AUTOSAR XML (schema 00050)
package /SwComponentTypes
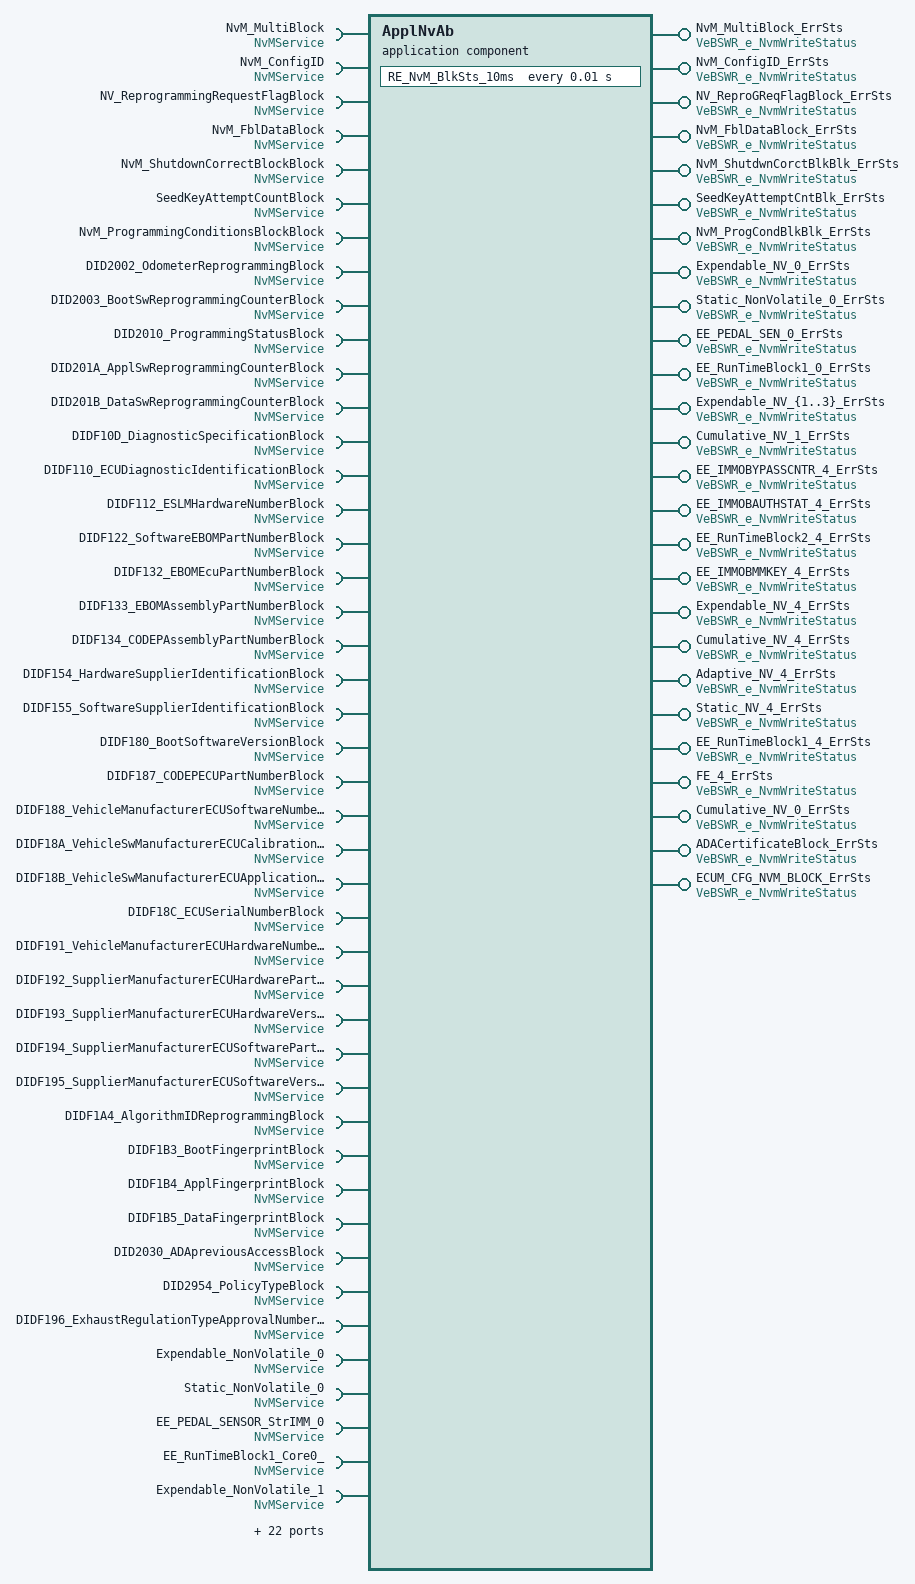
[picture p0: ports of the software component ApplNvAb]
  application sw component type ApplNvAb
    75 x require port, all with required-interface=NvMService:
      NvM_MultiBlock
      NvM_ConfigID
      NV_ReprogrammingRequestFlagBlock
      NvM_FblDataBlock
      NvM_ShutdownCorrectBlockBlock
      SeedKeyAttemptCountBlock
      NvM_ProgrammingConditionsBlockBlock
      DID2002_OdometerReprogrammingBlock
      DID2003_BootSwReprogrammingCounterBlock
      DID2010_ProgrammingStatusBlock
      DID201A_ApplSwReprogrammingCounterBlock
      DID201B_DataSwReprogrammingCounterBlock
      DIDF10D_DiagnosticSpecificationBlock
      DIDF110_ECUDiagnosticIdentificationBlock
      DIDF112_ESLMHardwareNumberBlock
      DIDF122_SoftwareEBOMPartNumberBlock
      DIDF132_EBOMEcuPartNumberBlock
      DIDF133_EBOMAssemblyPartNumberBlock
      DIDF134_CODEPAssemblyPartNumberBlock
      DIDF154_HardwareSupplierIdentificationBlock
      DIDF155_SoftwareSupplierIdentificationBlock
      DIDF180_BootSoftwareVersionBlock
      DIDF187_CODEPECUPartNumberBlock
      DIDF188_VehicleManufacturerECUSoftwareNumberBlock
      DIDF18A_VehicleSwManufacturerECUCalibrationNumberBlock
      DIDF18B_VehicleSwManufacturerECUApplicationNumberBlock
      DIDF18C_ECUSerialNumberBlock
      DIDF191_VehicleManufacturerECUHardwareNumberBlock
      DIDF192_SupplierManufacturerECUHardwarePartNumberBlock
      DIDF193_SupplierManufacturerECUHardwareVersionNumberBlock
      DIDF194_SupplierManufacturerECUSoftwarePartNumberBlock
      DIDF195_SupplierManufacturerECUSoftwareVersionNumberBlock
      DIDF1A4_AlgorithmIDReprogrammingBlock
      DIDF1B3_BootFingerprintBlock
      DIDF1B4_ApplFingerprintBlock
      DIDF1B5_DataFingerprintBlock
      DID2030_ADApreviousAccessBlock
      DID2954_PolicyTypeBlock
      DIDF196_ExhaustRegulationTypeApprovalNumberBlock
      Expendable_NonVolatile_0
      Static_NonVolatile_0
      EE_PEDAL_SENSOR_StrIMM_0
      EE_RunTimeBlock1_Core0_
      Expendable_NonVolatile_1
      Expendable_NonVolatile_Core2
      Expendable_NonVolatile_3
      Cumulative_NonVolatile_1
      EE_IMMOBYPASSCNTR_StrIMM_4
      EE_IMMOBILIZERAUTHSTAT_StrIMM_4
      EE_RunTimeBlock2_Core4
      EE_IMMOBILIZERMMKEY_StrIMM_4
      Expendable_NonVolatile_4
      Cumulative_NonVolatile_4
      Adaptive_NonVolatile_4
      Static_NonVolatile_4
      EE_RunTimeBlock1_Core4
      FE_4
      Cumulative_NonVolatile_0
      DID2023_PROXIWriteData
      BSWDiag_Data_blk_Desc_Core0
      NvM_Dem_IdIndicatorAttributes
      NvMBlockDescriptor_Dem_GenericNvData
      NvMBlockDescriptor_Dem_AllEventsStatusByte
      NvMBlockDescriptor_Dem_EvMemEventMemory{0..9}
      ADACertificateBlock
      ECUM_CFG_NVM_BLOCK
    28 x provide port, all with provided-interface=VeBSWR_e_NvmWriteStatus:
      NvM_MultiBlock_ErrSts
      NvM_ConfigID_ErrSts
      NV_ReproGReqFlagBlock_ErrSts
      NvM_FblDataBlock_ErrSts
      NvM_ShutdwnCorctBlkBlk_ErrSts
      SeedKeyAttemptCntBlk_ErrSts
      NvM_ProgCondBlkBlk_ErrSts
      Expendable_NV_0_ErrSts
      Static_NonVolatile_0_ErrSts
      EE_PEDAL_SEN_0_ErrSts
      EE_RunTimeBlock1_0_ErrSts
      Expendable_NV_{1..3}_ErrSts
      Cumulative_NV_1_ErrSts
      EE_IMMOBYPASSCNTR_4_ErrSts
      EE_IMMOBAUTHSTAT_4_ErrSts
      EE_RunTimeBlock2_4_ErrSts
      EE_IMMOBMMKEY_4_ErrSts
      Expendable_NV_4_ErrSts
      Cumulative_NV_4_ErrSts
      Adaptive_NV_4_ErrSts
      Static_NV_4_ErrSts
      EE_RunTimeBlock1_4_ErrSts
      FE_4_ErrSts
      Cumulative_NV_0_ErrSts
      ADACertificateBlock_ErrSts
      ECUM_CFG_NVM_BLOCK_ErrSts
    behavior IBApplNvAb
      timing event RE_NvM_BlkErrSts_10ms: start-on-event=RE_NvM_BlkSts_10ms, period=0.01
      runnable RE_NvM_BlkSts_10ms
        data-send-points:
          28 x access:
            DSP_VeBSWR_e_NvmWriteStatus_0: accessed-variable=ADACertificateBlock_ErrSts.VeBSWR_e_NvmWriteStatus
            DSP_VeBSWR_e_NvmWriteStatus_1: accessed-variable=Cumulative_NV_4_ErrSts.VeBSWR_e_NvmWriteStatus
            DSP_VeBSWR_e_NvmWriteStatus_2: accessed-variable=SeedKeyAttemptCntBlk_ErrSts.VeBSWR_e_NvmWriteStatus
            DSP_VeBSWR_e_NvmWriteStatus_3: accessed-variable=Expendable_NV_3_ErrSts.VeBSWR_e_NvmWriteStatus
            DSP_VeBSWR_e_NvmWriteStatus_4: accessed-variable=Cumulative_NV_1_ErrSts.VeBSWR_e_NvmWriteStatus
            DSP_VeBSWR_e_NvmWriteStatus_5: accessed-variable=NvM_ShutdwnCorctBlkBlk_ErrSts.VeBSWR_e_NvmWriteStatus
            DSP_VeBSWR_e_NvmWriteStatus_6: accessed-variable=Expendable_NV_1_ErrSts.VeBSWR_e_NvmWriteStatus
            DSP_VeBSWR_e_NvmWriteStatus_7: accessed-variable=NvM_MultiBlock_ErrSts.VeBSWR_e_NvmWriteStatus
            DSP_VeBSWR_e_NvmWriteStatus_8: accessed-variable=EE_IMMOBYPASSCNTR_4_ErrSts.VeBSWR_e_NvmWriteStatus
            DSP_VeBSWR_e_NvmWriteStatus_9: accessed-variable=Expendable_NV_0_ErrSts.VeBSWR_e_NvmWriteStatus
            DSP_VeBSWR_e_NvmWriteStatus_10: accessed-variable=Expendable_NV_4_ErrSts.VeBSWR_e_NvmWriteStatus
            DSP_VeBSWR_e_NvmWriteStatus_11: accessed-variable=NV_ReproGReqFlagBlock_ErrSts.VeBSWR_e_NvmWriteStatus
            DSP_VeBSWR_e_NvmWriteStatus_12: accessed-variable=FE_4_ErrSts.VeBSWR_e_NvmWriteStatus
            DSP_VeBSWR_e_NvmWriteStatus_13: accessed-variable=EE_RunTimeBlock2_4_ErrSts.VeBSWR_e_NvmWriteStatus
            DSP_VeBSWR_e_NvmWriteStatus_14: accessed-variable=Static_NonVolatile_0_ErrSts.VeBSWR_e_NvmWriteStatus
            DSP_VeBSWR_e_NvmWriteStatus_15: accessed-variable=EE_RunTimeBlock1_0_ErrSts.VeBSWR_e_NvmWriteStatus
            DSP_VeBSWR_e_NvmWriteStatus_16: accessed-variable=NvM_ConfigID_ErrSts.VeBSWR_e_NvmWriteStatus
            DSP_VeBSWR_e_NvmWriteStatus_17: accessed-variable=Expendable_NV_2_ErrSts.VeBSWR_e_NvmWriteStatus
            DSP_VeBSWR_e_NvmWriteStatus_18: accessed-variable=EE_IMMOBAUTHSTAT_4_ErrSts.VeBSWR_e_NvmWriteStatus
            DSP_VeBSWR_e_NvmWriteStatus_19: accessed-variable=Static_NV_4_ErrSts.VeBSWR_e_NvmWriteStatus
            DSP_VeBSWR_e_NvmWriteStatus_20: accessed-variable=EE_IMMOBMMKEY_4_ErrSts.VeBSWR_e_NvmWriteStatus
            DSP_VeBSWR_e_NvmWriteStatus_21: accessed-variable=ECUM_CFG_NVM_BLOCK_ErrSts.VeBSWR_e_NvmWriteStatus
            DSP_VeBSWR_e_NvmWriteStatus_22: accessed-variable=Adaptive_NV_4_ErrSts.VeBSWR_e_NvmWriteStatus
            DSP_VeBSWR_e_NvmWriteStatus_23: accessed-variable=EE_RunTimeBlock1_4_ErrSts.VeBSWR_e_NvmWriteStatus
            DSP_VeBSWR_e_NvmWriteStatus_24: accessed-variable=NvM_FblDataBlock_ErrSts.VeBSWR_e_NvmWriteStatus
            DSP_VeBSWR_e_NvmWriteStatus_25: accessed-variable=EE_PEDAL_SEN_0_ErrSts.VeBSWR_e_NvmWriteStatus
            DSP_VeBSWR_e_NvmWriteStatus_26: accessed-variable=Cumulative_NV_0_ErrSts.VeBSWR_e_NvmWriteStatus
            DSP_VeBSWR_e_NvmWriteStatus_27: accessed-variable=NvM_ProgCondBlkBlk_ErrSts.VeBSWR_e_NvmWriteStatus
        75 x sync call:
          SynchronousServerCallPoint_0: operation=NvM_MultiBlock.GetErrorStatus
          SynchronousServerCallPoint_1: operation=NvM_ConfigID.GetErrorStatus
          SynchronousServerCallPoint_2: operation=NV_ReprogrammingRequestFlagBlock.GetErrorStatus
          SynchronousServerCallPoint_3: operation=NvM_FblDataBlock.GetErrorStatus
          SynchronousServerCallPoint_4: operation=NvM_ShutdownCorrectBlockBlock.GetErrorStatus
          SynchronousServerCallPoint_5: operation=SeedKeyAttemptCountBlock.GetErrorStatus
          SynchronousServerCallPoint_6: operation=NvM_ProgrammingConditionsBlockBlock.GetErrorStatus
          SynchronousServerCallPoint_7: operation=DID2002_OdometerReprogrammingBlock.GetErrorStatus
          SynchronousServerCallPoint_8: operation=DID2003_BootSwReprogrammingCounterBlock.GetErrorStatus
          SynchronousServerCallPoint_9: operation=DID2010_ProgrammingStatusBlock.GetErrorStatus
          SynchronousServerCallPoint_10: operation=DID201A_ApplSwReprogrammingCounterBlock.GetErrorStatus
          SynchronousServerCallPoint_11: operation=DID201B_DataSwReprogrammingCounterBlock.GetErrorStatus
          SynchronousServerCallPoint_12: operation=DIDF10D_DiagnosticSpecificationBlock.GetErrorStatus
          SynchronousServerCallPoint_13: operation=DIDF110_ECUDiagnosticIdentificationBlock.GetErrorStatus
          SynchronousServerCallPoint_14: operation=DIDF112_ESLMHardwareNumberBlock.GetErrorStatus
          SynchronousServerCallPoint_15: operation=DIDF122_SoftwareEBOMPartNumberBlock.GetErrorStatus
          SynchronousServerCallPoint_16: operation=DIDF132_EBOMEcuPartNumberBlock.GetErrorStatus
          SynchronousServerCallPoint_17: operation=DIDF133_EBOMAssemblyPartNumberBlock.GetErrorStatus
          SynchronousServerCallPoint_18: operation=DIDF134_CODEPAssemblyPartNumberBlock.GetErrorStatus
          SynchronousServerCallPoint_19: operation=DIDF154_HardwareSupplierIdentificationBlock.GetErrorStatus
          SynchronousServerCallPoint_20: operation=DIDF155_SoftwareSupplierIdentificationBlock.GetErrorStatus
          SynchronousServerCallPoint_21: operation=DIDF180_BootSoftwareVersionBlock.GetErrorStatus
          SynchronousServerCallPoint_22: operation=DIDF187_CODEPECUPartNumberBlock.GetErrorStatus
          SynchronousServerCallPoint_23: operation=DIDF188_VehicleManufacturerECUSoftwareNumberBlock.GetErrorStatus
          SynchronousServerCallPoint_24: operation=DIDF18A_VehicleSwManufacturerECUCalibrationNumberBlock.GetErrorStatus
          SynchronousServerCallPoint_25: operation=DIDF18B_VehicleSwManufacturerECUApplicationNumberBlock.GetErrorStatus
          SynchronousServerCallPoint_26: operation=DIDF18C_ECUSerialNumberBlock.GetErrorStatus
          SynchronousServerCallPoint_27: operation=DIDF191_VehicleManufacturerECUHardwareNumberBlock.GetErrorStatus
          SynchronousServerCallPoint_28: operation=DIDF192_SupplierManufacturerECUHardwarePartNumberBlock.GetErrorStatus
          SynchronousServerCallPoint_29: operation=DIDF193_SupplierManufacturerECUHardwareVersionNumberBlock.GetErrorStatus
          SynchronousServerCallPoint_30: operation=DIDF194_SupplierManufacturerECUSoftwarePartNumberBlock.GetErrorStatus
          SynchronousServerCallPoint_31: operation=DIDF195_SupplierManufacturerECUSoftwareVersionNumberBlock.GetErrorStatus
          SynchronousServerCallPoint_32: operation=DIDF1A4_AlgorithmIDReprogrammingBlock.GetErrorStatus
          SynchronousServerCallPoint_33: operation=DIDF1B3_BootFingerprintBlock.GetErrorStatus
          SynchronousServerCallPoint_34: operation=DIDF1B4_ApplFingerprintBlock.GetErrorStatus
          SynchronousServerCallPoint_35: operation=DIDF1B5_DataFingerprintBlock.GetErrorStatus
          SynchronousServerCallPoint_36: operation=DID2030_ADApreviousAccessBlock.GetErrorStatus
          SynchronousServerCallPoint_37: operation=DID2954_PolicyTypeBlock.GetErrorStatus
          SynchronousServerCallPoint_38: operation=DIDF196_ExhaustRegulationTypeApprovalNumberBlock.GetErrorStatus
          SynchronousServerCallPoint_39: operation=Expendable_NonVolatile_0.GetErrorStatus
          SynchronousServerCallPoint_40: operation=Static_NonVolatile_0.GetErrorStatus
          SynchronousServerCallPoint_41: operation=EE_PEDAL_SENSOR_StrIMM_0.GetErrorStatus
          SynchronousServerCallPoint_42: operation=EE_RunTimeBlock1_Core0_.GetErrorStatus
          SynchronousServerCallPoint_43: operation=Expendable_NonVolatile_1.GetErrorStatus
          SynchronousServerCallPoint_44: operation=Expendable_NonVolatile_Core2.GetErrorStatus
          SynchronousServerCallPoint_45: operation=Expendable_NonVolatile_3.GetErrorStatus
          SynchronousServerCallPoint_46: operation=Cumulative_NonVolatile_1.GetErrorStatus
          SynchronousServerCallPoint_47: operation=EE_IMMOBYPASSCNTR_StrIMM_4.GetErrorStatus
          SynchronousServerCallPoint_48: operation=EE_IMMOBILIZERAUTHSTAT_StrIMM_4.GetErrorStatus
          SynchronousServerCallPoint_49: operation=EE_RunTimeBlock2_Core4.GetErrorStatus
          SynchronousServerCallPoint_50: operation=EE_IMMOBILIZERMMKEY_StrIMM_4.GetErrorStatus
          SynchronousServerCallPoint_51: operation=Expendable_NonVolatile_4.GetErrorStatus
          SynchronousServerCallPoint_52: operation=Cumulative_NonVolatile_4.GetErrorStatus
          SynchronousServerCallPoint_53: operation=Adaptive_NonVolatile_4.GetErrorStatus
          SynchronousServerCallPoint_54: operation=Static_NonVolatile_4.GetErrorStatus
          SynchronousServerCallPoint_55: operation=EE_RunTimeBlock1_Core4.GetErrorStatus
          SynchronousServerCallPoint_56: operation=FE_4.GetErrorStatus
          SynchronousServerCallPoint_57: operation=Cumulative_NonVolatile_0.GetErrorStatus
          SynchronousServerCallPoint_58: operation=DID2023_PROXIWriteData.GetErrorStatus
          SynchronousServerCallPoint_59: operation=BSWDiag_Data_blk_Desc_Core0.GetErrorStatus
          SynchronousServerCallPoint_60: operation=NvM_Dem_IdIndicatorAttributes.GetErrorStatus
          SynchronousServerCallPoint_61: operation=NvMBlockDescriptor_Dem_GenericNvData.GetErrorStatus
          SynchronousServerCallPoint_62: operation=NvMBlockDescriptor_Dem_AllEventsStatusByte.GetErrorStatus
          SynchronousServerCallPoint_63: operation=NvMBlockDescriptor_Dem_EvMemEventMemory0.GetErrorStatus
          SynchronousServerCallPoint_64: operation=NvMBlockDescriptor_Dem_EvMemEventMemory1.GetErrorStatus
          SynchronousServerCallPoint_65: operation=NvMBlockDescriptor_Dem_EvMemEventMemory2.GetErrorStatus
          SynchronousServerCallPoint_66: operation=NvMBlockDescriptor_Dem_EvMemEventMemory3.GetErrorStatus
          SynchronousServerCallPoint_67: operation=NvMBlockDescriptor_Dem_EvMemEventMemory4.GetErrorStatus
          SynchronousServerCallPoint_68: operation=NvMBlockDescriptor_Dem_EvMemEventMemory5.GetErrorStatus
          SynchronousServerCallPoint_69: operation=NvMBlockDescriptor_Dem_EvMemEventMemory6.GetErrorStatus
          SynchronousServerCallPoint_70: operation=NvMBlockDescriptor_Dem_EvMemEventMemory7.GetErrorStatus
          SynchronousServerCallPoint_71: operation=NvMBlockDescriptor_Dem_EvMemEventMemory8.GetErrorStatus
          SynchronousServerCallPoint_72: operation=NvMBlockDescriptor_Dem_EvMemEventMemory9.GetErrorStatus
          SynchronousServerCallPoint_73: operation=ADACertificateBlock.GetErrorStatus
          SynchronousServerCallPoint_74: operation=ECUM_CFG_NVM_BLOCK.GetErrorStatus
